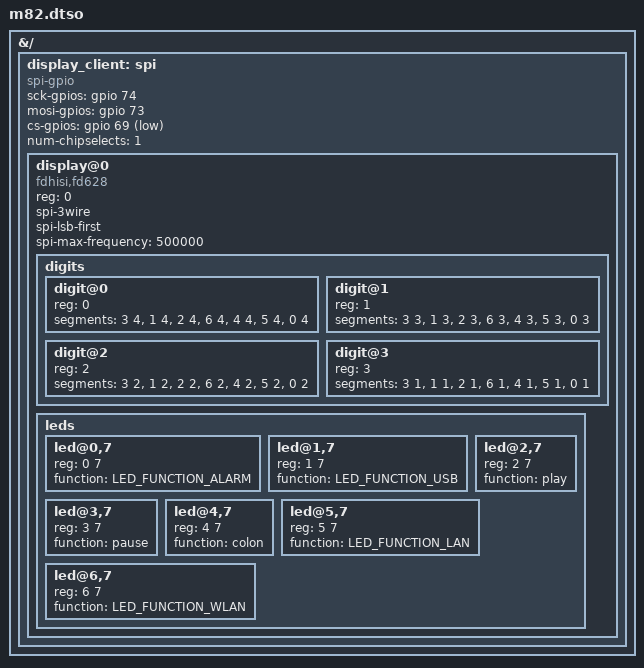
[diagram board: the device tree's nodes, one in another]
/dts-v1/;
/plugin/;

#include <dt-bindings/gpio/gpio.h>
#include <dt-bindings/leds/common.h>

&{/} {

	display_client: spi {
		#address-cells = <1>;
		#size-cells = <0>;
		compatible = "spi-gpio";
		sck-gpios = <&gpio 74 GPIO_ACTIVE_HIGH>;
		mosi-gpios = <&gpio 73 GPIO_ACTIVE_HIGH>;
		cs-gpios = <&gpio 69 GPIO_ACTIVE_LOW>;
		num-chipselects = <1>;

		display@0 {
			compatible = "fdhisi,fd628", "titanmec,tm1628";
			reg = <0>;
			spi-3wire;
			spi-lsb-first;
			spi-max-frequency = <500000>;

			digits {
				#address-cells = <1>;
				#size-cells = <0>;
				digit@0 {
					reg = <0>;
					segments = <3 4>,
						   <1 4>,
						   <2 4>,
						   <6 4>,
						   <4 4>,
						   <5 4>,
						   <0 4>;
				};
				digit@1 {
					reg = <1>;
					segments = <3 3>,
						   <1 3>,
						   <2 3>,
						   <6 3>,
						   <4 3>,
						   <5 3>,
						   <0 3>;
				};
				digit@2 {
					reg = <2>;
					segments = <3 2>,
						   <1 2>,
						   <2 2>,
						   <6 2>,
						   <4 2>,
						   <5 2>,
						   <0 2>;
				};
				digit@3 {
					reg = <3>;
					segments = <3 1>,
						   <1 1>,
						   <2 1>,
						   <6 1>,
						   <4 1>,
						   <5 1>,
						   <0 1>;
				};
			};

			leds {
				#address-cells = <2>;
				#size-cells = <0>;
				led@0,7 {
					reg = <0 7>;
					function = LED_FUNCTION_ALARM;
				};
				led@1,7 {
					reg = <1 7>;
					function = LED_FUNCTION_USB;
				};
				led@2,7 {
					reg = <2 7>;
					function = "play";
				};
				led@3,7 {
					reg = <3 7>;
					function = "pause";
				};
				led@4,7 {
					reg = <4 7>;
					function = "colon";
				};
				led@5,7 {
					reg = <5 7>;
					function = LED_FUNCTION_LAN;
				};
				led@6,7 {
					reg = <6 7>;
					function = LED_FUNCTION_WLAN;
				};
			};
		};
	};
};
